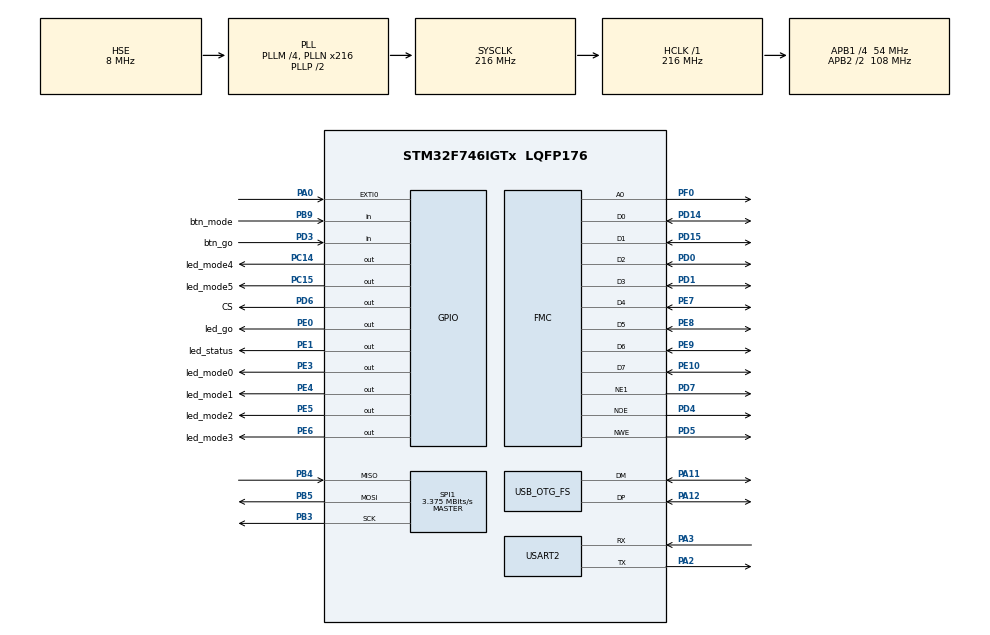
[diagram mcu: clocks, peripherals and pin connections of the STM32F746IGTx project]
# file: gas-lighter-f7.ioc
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CORTEX_M7.MPU_Control=__NULL
CORTEX_M7.default_mode_Activation=0
Dma.MEMTOMEM.0.Direction=DMA_MEMORY_TO_MEMORY
Dma.MEMTOMEM.0.FIFOMode=DMA_FIFOMODE_ENABLE
Dma.MEMTOMEM.0.FIFOThreshold=DMA_FIFO_THRESHOLD_FULL
Dma.MEMTOMEM.0.Instance=DMA2_Stream0
Dma.MEMTOMEM.0.MemBurst=DMA_MBURST_SINGLE
Dma.MEMTOMEM.0.MemDataAlignment=DMA_MDATAALIGN_BYTE
Dma.MEMTOMEM.0.MemInc=DMA_MINC_DISABLE
Dma.MEMTOMEM.0.Mode=DMA_NORMAL
Dma.MEMTOMEM.0.PeriphBurst=DMA_PBURST_SINGLE
Dma.MEMTOMEM.0.PeriphDataAlignment=DMA_PDATAALIGN_BYTE
Dma.MEMTOMEM.0.PeriphInc=DMA_PINC_ENABLE
Dma.MEMTOMEM.0.Priority=DMA_PRIORITY_VERY_HIGH
Dma.Request0=MEMTOMEM
FMC.AddressSetupTime1=0
FMC.BusTurnAroundDuration1=1
FMC.DataSetupTime1=1
FMC.WriteOperation1=FMC_WRITE_OPERATION_ENABLE
Mcu.Family=STM32F7
Mcu.Name=STM32F746IGTx
Mcu.Package=LQFP176
NVIC.EXTI0_IRQn=true\:5\:0\:true\:false\:true\:true\:true\:true
NVIC.OTG_FS_IRQn=true\:5\:0\:true\:false\:true\:true\:true\:true
NVIC.PriorityGroup=NVIC_PRIORITYGROUP_4
NVIC.TIM1_UP_TIM10_IRQn=true\:15\:0\:false\:false\:true\:false\:true\:true
NVIC.TimeBase=TIM1_UP_TIM10_IRQn
NVIC.TimeBaseIP=TIM1
PA0/WKUP.GPIO_ModeDefaultEXTI=GPIO_MODE_IT_FALLING
PA0/WKUP.GPIO_PuPd=GPIO_PULLUP
PA0/WKUP.Signal=GPXTI0
PA11.Mode=Device_Only
PA11.Signal=USB_OTG_FS_DM
PA12.Mode=Device_Only
PA12.Signal=USB_OTG_FS_DP
PA13.Mode=Serial_Wire
PA13.Signal=SYS_JTMS-SWDIO
PA14.Mode=Serial_Wire
PA14.Signal=SYS_JTCK-SWCLK
PA2.Mode=Asynchronous
PA2.Signal=USART2_TX
PA3.Mode=Asynchronous
PA3.Signal=USART2_RX
PB3.Mode=Full_Duplex_Master
PB3.Signal=SPI1_SCK
PB4.Mode=Full_Duplex_Master
PB4.Signal=SPI1_MISO
PB5.Mode=Full_Duplex_Master
PB5.Signal=SPI1_MOSI
PB6.Signal=USART1_TX
PB7.Signal=USART1_RX
PB9.GPIO_Label=btn_mode
PB9.GPIO_PuPd=GPIO_PULLUP
PB9.Signal=GPIO_Input
PC14/OSC32_IN.GPIO_Label=led_mode4
PC14/OSC32_IN.Signal=GPIO_Output
PC15/OSC32_OUT.GPIO_Label=led_mode5
PC15/OSC32_OUT.Signal=GPIO_Output
PD0.Signal=FMC_D2_DA2
PD1.Signal=FMC_D3_DA3
PD14.Signal=FMC_D0_DA0
PD15.Signal=FMC_D1_DA1
PD3.GPIO_Label=btn_go
PD3.GPIO_PuPd=GPIO_PULLUP
PD3.Signal=GPIO_Input
PD4.Signal=FMC_NOE
PD5.Signal=FMC_NWE
PD6.GPIO_Label=CS
PD6.GPIO_Speed=GPIO_SPEED_FREQ_VERY_HIGH
PD6.PinState=GPIO_PIN_SET
PD6.Signal=GPIO_Output
PD7.Mode=NorPsramChipSelect1_1
PD7.Signal=FMC_NE1
PE0.GPIO_Label=led_go
PE0.Signal=GPIO_Output
PE1.GPIO_Label=led_status
PE1.Signal=GPIO_Output
PE10.Signal=FMC_D7_DA7
PE3.GPIO_Label=led_mode0
PE3.Signal=GPIO_Output
PE4.GPIO_Label=led_mode1
PE4.Signal=GPIO_Output
PE5.GPIO_Label=led_mode2
PE5.Signal=GPIO_Output
PE6.GPIO_Label=led_mode3
PE6.Signal=GPIO_Output
PE7.Signal=FMC_D4_DA4
PE8.Signal=FMC_D5_DA5
PE9.Signal=FMC_D6_DA6
PF0.Signal=FMC_A0
PH0/OSC_IN.Mode=HSE-External-Oscillator
PH0/OSC_IN.Signal=RCC_OSC_IN
PH1/OSC_OUT.Mode=HSE-External-Oscillator
PH1/OSC_OUT.Signal=RCC_OSC_OUT
ProjectManager.HeapSize=0x200
ProjectManager.StackSize=0x400
ProjectManager.TargetToolchain=CMake
RCC.AHBFreq_Value=216000000
RCC.APB1CLKDivider=RCC_HCLK_DIV4
RCC.APB1Freq_Value=54000000
RCC.APB1TimFreq_Value=108000000
RCC.APB2CLKDivider=RCC_HCLK_DIV2
RCC.APB2Freq_Value=108000000
RCC.APB2TimFreq_Value=216000000
RCC.CortexFreq_Value=216000000
RCC.HCLKFreq_Value=216000000
RCC.HSE_VALUE=8000000
RCC.HSI_VALUE=16000000
RCC.LSE_VALUE=32768
RCC.PLLM=4
RCC.PLLN=216
RCC.PLLQ=9
RCC.SYSCLKFreq_VALUE=216000000
RCC.SYSCLKSource=RCC_SYSCLKSOURCE_PLLCLK
RCC.USBFreq_Value=48000000
RCC.VCOOutputFreq_Value=432000000
SH.FMC_A0.0=FMC_A0,1b-a1
SH.FMC_D0_DA0.0=FMC_D0,8b-d1
SH.FMC_D1_DA1.0=FMC_D1,8b-d1
SH.FMC_D2_DA2.0=FMC_D2,8b-d1
SH.FMC_D3_DA3.0=FMC_D3,8b-d1
SH.FMC_D4_DA4.0=FMC_D4,8b-d1
SH.FMC_D5_DA5.0=FMC_D5,8b-d1
SH.FMC_D6_DA6.0=FMC_D6,8b-d1
SH.FMC_D7_DA7.0=FMC_D7,8b-d1
SH.FMC_NOE.0=FMC_NOE,Sram1
SH.FMC_NWE.0=FMC_NWE,Sram1
SPI1.BaudRatePrescaler=SPI_BAUDRATEPRESCALER_32
SPI1.CalculateBaudRate=3.375 MBits/s
SPI1.DataSize=SPI_DATASIZE_8BIT
SPI1.Direction=SPI_DIRECTION_2LINES
SPI1.Mode=SPI_MODE_MASTER
SPI1.NSSPMode=SPI_NSS_PULSE_DISABLE
SPI1.VirtualType=VM_MASTER
USART2.VirtualMode-Asynchronous=VM_ASYNC
USB_OTG_FS.VirtualMode=Device_Only
VP_SYS_VS_tim1.Mode=TIM1
board=custom

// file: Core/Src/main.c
/* USER CODE BEGIN Header */
/**
  ******************************************************************************
  * @file           : main.c
  * @brief          : Main program body
  ******************************************************************************
  * @attention
  *
  * Copyright (c) 2026 STMicroelectronics.
  * All rights reserved.
  *
  * This software is licensed under terms that can be found in the LICENSE file
  * in the root directory of this software component.
  * If no LICENSE file comes with this software, it is provided AS-IS.
  *
  ******************************************************************************
  */
/* USER CODE END Header */
#include "main.h"
#include "dma.h"
#include "spi.h"
#include "usart.h"
#include "usb_otg.h"
#include "gpio.h"
#include "fmc.h"

/* USER CODE BEGIN Includes */
#include "app.h"
/* USER CODE END Includes */

void SystemClock_Config(void);

int main(void)
{

  /* MCU Configuration--------------------------------------------------------*/

  /* Reset of all peripherals, Initializes the Flash interface and the Systick. */
  HAL_Init();

  /* USER CODE BEGIN Init */
  init();
  /* USER CODE END Init */

  /* Configure the system clock */
  SystemClock_Config();

  /* Initialize all configured peripherals */
  MX_GPIO_Init();
  MX_DMA_Init();
  MX_SPI1_Init();
  MX_USB_OTG_FS_PCD_Init();
  MX_FMC_Init();
  MX_USART2_UART_Init();
  /* USER CODE BEGIN 2 */
  setup();
  /* USER CODE END 2 */

  /* Infinite loop */
  while (1)
  {

  }
}

void SystemClock_Config(void)
{
  RCC_OscInitTypeDef RCC_OscInitStruct = {0};
  RCC_ClkInitTypeDef RCC_ClkInitStruct = {0};

  /** Configure the main internal regulator output voltage
  */
  __HAL_RCC_PWR_CLK_ENABLE();
  __HAL_PWR_VOLTAGESCALING_CONFIG(PWR_REGULATOR_VOLTAGE_SCALE1);

  /** Initializes the RCC Oscillators according to the specified parameters
  * in the RCC_OscInitTypeDef structure.
  */
  RCC_OscInitStruct.OscillatorType = RCC_OSCILLATORTYPE_HSE;
  RCC_OscInitStruct.HSEState = RCC_HSE_ON;
  RCC_OscInitStruct.PLL.PLLState = RCC_PLL_ON;
  RCC_OscInitStruct.PLL.PLLSource = RCC_PLLSOURCE_HSE;
  RCC_OscInitStruct.PLL.PLLM = 4;
  RCC_OscInitStruct.PLL.PLLN = 216;
  RCC_OscInitStruct.PLL.PLLP = RCC_PLLP_DIV2;
  RCC_OscInitStruct.PLL.PLLQ = 9;
  if (HAL_RCC_OscConfig(&RCC_OscInitStruct) != HAL_OK)
  {
    Error_Handler();
  }

  /** Activate the Over-Drive mode
  */
  if (HAL_PWREx_EnableOverDrive() != HAL_OK)
  {
    Error_Handler();
  }

  /** Initializes the CPU, AHB and APB buses clocks
  */
  RCC_ClkInitStruct.ClockType = RCC_CLOCKTYPE_HCLK|RCC_CLOCKTYPE_SYSCLK
                              |RCC_CLOCKTYPE_PCLK1|RCC_CLOCKTYPE_PCLK2;
  RCC_ClkInitStruct.SYSCLKSource = RCC_SYSCLKSOURCE_PLLCLK;
  RCC_ClkInitStruct.AHBCLKDivider = RCC_SYSCLK_DIV1;
  RCC_ClkInitStruct.APB1CLKDivider = RCC_HCLK_DIV4;
  RCC_ClkInitStruct.APB2CLKDivider = RCC_HCLK_DIV2;

  if (HAL_RCC_ClockConfig(&RCC_ClkInitStruct, FLASH_LATENCY_7) != HAL_OK)
  {
    Error_Handler();
  }
}

void HAL_TIM_PeriodElapsedCallback(TIM_HandleTypeDef *htim)
{
  if (htim->Instance == TIM1)
  {
    HAL_IncTick();
  }
}

void Error_Handler(void)
{
  __disable_irq();
  while (1)
  {
  }
}
